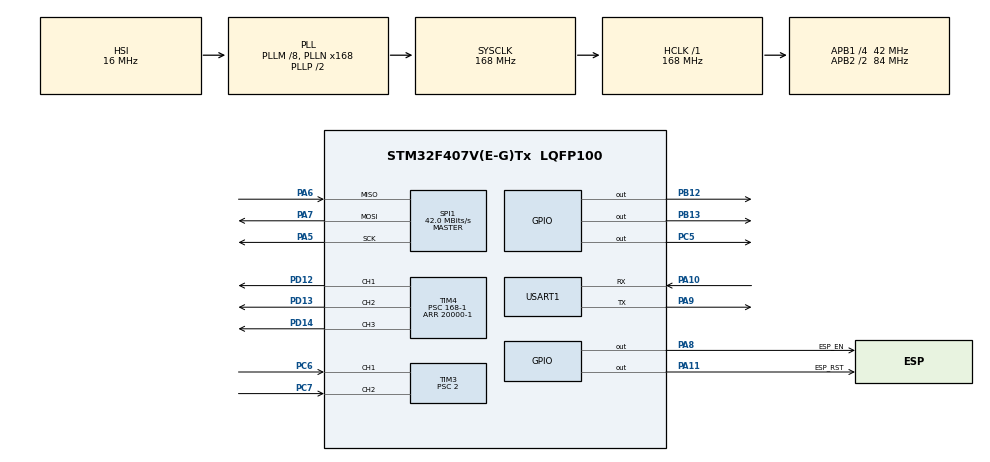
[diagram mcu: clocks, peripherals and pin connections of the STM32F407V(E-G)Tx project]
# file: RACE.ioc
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Dma.Request0=USART1_TX
Dma.Request1=USART1_RX
Dma.USART1_RX.1.Direction=DMA_PERIPH_TO_MEMORY
Dma.USART1_RX.1.FIFOMode=DMA_FIFOMODE_DISABLE
Dma.USART1_RX.1.Instance=DMA2_Stream2
Dma.USART1_RX.1.MemDataAlignment=DMA_MDATAALIGN_BYTE
Dma.USART1_RX.1.MemInc=DMA_MINC_ENABLE
Dma.USART1_RX.1.Mode=DMA_NORMAL
Dma.USART1_RX.1.PeriphDataAlignment=DMA_PDATAALIGN_BYTE
Dma.USART1_RX.1.PeriphInc=DMA_PINC_DISABLE
Dma.USART1_RX.1.Priority=DMA_PRIORITY_LOW
Dma.USART1_TX.0.Direction=DMA_MEMORY_TO_PERIPH
Dma.USART1_TX.0.FIFOMode=DMA_FIFOMODE_DISABLE
Dma.USART1_TX.0.Instance=DMA2_Stream7
Dma.USART1_TX.0.MemDataAlignment=DMA_MDATAALIGN_BYTE
Dma.USART1_TX.0.MemInc=DMA_MINC_ENABLE
Dma.USART1_TX.0.Mode=DMA_NORMAL
Dma.USART1_TX.0.PeriphDataAlignment=DMA_PDATAALIGN_BYTE
Dma.USART1_TX.0.PeriphInc=DMA_PINC_DISABLE
Dma.USART1_TX.0.Priority=DMA_PRIORITY_LOW
Mcu.Family=STM32F4
Mcu.Name=STM32F407V(E-G)Tx
Mcu.Package=LQFP100
NVIC.DMA2_Stream2_IRQn=true\:0\:0\:false\:false\:true\:false\:true\:true
NVIC.DMA2_Stream7_IRQn=true\:0\:0\:false\:false\:true\:false\:true\:true
NVIC.PriorityGroup=NVIC_PRIORITYGROUP_4
NVIC.TIM1_UP_TIM10_IRQn=true\:0\:0\:false\:false\:true\:true\:true\:true
NVIC.USART1_IRQn=true\:0\:0\:false\:false\:true\:true\:true\:true
PA10.Mode=Asynchronous
PA10.Signal=USART1_RX
PA11.GPIO_Label=ESP_RST
PA11.PinState=GPIO_PIN_SET
PA11.Signal=GPIO_Output
PA5.Mode=Full_Duplex_Master
PA5.Signal=SPI1_SCK
PA6.Mode=Full_Duplex_Master
PA6.Signal=SPI1_MISO
PA7.Mode=Full_Duplex_Master
PA7.Signal=SPI1_MOSI
PA8.GPIO_Label=ESP_EN
PA8.PinState=GPIO_PIN_RESET
PA8.Signal=GPIO_Output
PA9.Mode=Asynchronous
PA9.Signal=USART1_TX
PB12.Signal=GPIO_Output
PB13.Signal=GPIO_Output
PC5.Signal=GPIO_Output
PC6.Signal=S_TIM3_CH1
PC7.Signal=S_TIM3_CH2
PD12.Signal=S_TIM4_CH1
PD13.Signal=S_TIM4_CH2
PD14.Signal=S_TIM4_CH3
PH0-OSC_IN.Mode=HSE-External-Oscillator
PH0-OSC_IN.Signal=RCC_OSC_IN
PH1-OSC_OUT.Mode=HSE-External-Oscillator
PH1-OSC_OUT.Signal=RCC_OSC_OUT
ProjectManager.HeapSize=0x1000
ProjectManager.StackSize=0x2000
ProjectManager.TargetToolchain=MDK-ARM V5.32
RCC.48MHZClocksFreq_Value=84000000
RCC.AHBFreq_Value=168000000
RCC.APB1CLKDivider=RCC_HCLK_DIV4
RCC.APB1Freq_Value=42000000
RCC.APB1TimFreq_Value=84000000
RCC.APB2CLKDivider=RCC_HCLK_DIV2
RCC.APB2Freq_Value=84000000
RCC.APB2TimFreq_Value=168000000
RCC.CortexFreq_Value=168000000
RCC.HCLKFreq_Value=168000000
RCC.HSE_VALUE=25000000
RCC.HSI_VALUE=16000000
RCC.LSE_VALUE=32768
RCC.PLLM=8
RCC.PLLN=168
RCC.SYSCLKFreq_VALUE=168000000
RCC.SYSCLKSource=RCC_SYSCLKSOURCE_PLLCLK
RCC.VCOOutputFreq_Value=336000000
SH.S_TIM3_CH1.0=TIM3_CH1,Encoder_Interface
SH.S_TIM3_CH2.0=TIM3_CH2,Encoder_Interface
SH.S_TIM4_CH1.0=TIM4_CH1,PWM Generation1 CH1
SH.S_TIM4_CH2.0=TIM4_CH2,PWM Generation2 CH2
SH.S_TIM4_CH3.0=TIM4_CH3,PWM Generation3 CH3
SPI1.CalculateBaudRate=42.0 MBits/s
SPI1.Direction=SPI_DIRECTION_2LINES
SPI1.Mode=SPI_MODE_MASTER
SPI1.VirtualType=VM_MASTER
TIM1.Period=1000
TIM1.Prescaler=168
TIM3.Prescaler=2
TIM4.Channel-PWM\ Generation1\ CH1=TIM_CHANNEL_1
TIM4.Channel-PWM\ Generation2\ CH2=TIM_CHANNEL_2
TIM4.Channel-PWM\ Generation3\ CH3=TIM_CHANNEL_3
TIM4.Period=20000-1
TIM4.Prescaler=168-1
USART1.VirtualMode=VM_ASYNC
VP_TIM1_VS_ClockSourceINT.Mode=Internal
board=custom

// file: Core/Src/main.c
/* USER CODE BEGIN Header */
/**
  ******************************************************************************
  * @file           : main.c
  * @brief          : Main program body
  ******************************************************************************
  * @attention
  *
  * Copyright (c) 2024 STMicroelectronics.
  * All rights reserved.
  *
  * This software is licensed under terms that can be found in the LICENSE file
  * in the root directory of this software component.
  * If no LICENSE file comes with this software, it is provided AS-IS.
  *
  ******************************************************************************
  */
/* USER CODE END Header */
#include "main.h"
#include "dma.h"
#include "spi.h"
#include "tim.h"
#include "usart.h"
#include "gpio.h"

/* USER CODE BEGIN Includes */
#include "Deploy.h"
/* USER CODE END Includes */

void SystemClock_Config(void);
/* USER CODE BEGIN PFP */
void HAL_TIM_PeriodElapsedCallback(TIM_HandleTypeDef *htim){
	if(htim==&htim1)interrupt_all();
}
void HAL_UARTEx_RxEventCallback(UART_HandleTypeDef *huart, uint16_t Size){
	esp01s_callback_Rx(huart,Size);
}
void HAL_UART_TxCpltCallback(UART_HandleTypeDef *huart){
	esp01s_callback_Tx(huart);
}
/* USER CODE END PFP */

int main(void)
{

  /* MCU Configuration--------------------------------------------------------*/

  /* Reset of all peripherals, Initializes the Flash interface and the Systick. */
  HAL_Init();

  /* Configure the system clock */
  SystemClock_Config();

  /* Initialize all configured peripherals */
  MX_GPIO_Init();
  MX_DMA_Init();
  MX_TIM1_Init();
  MX_TIM4_Init();
  MX_TIM3_Init();
  MX_USART1_UART_Init();
  MX_SPI1_Init();
  /* USER CODE BEGIN 2 */
	init_all();
  /* USER CODE END 2 */

  /* Infinite loop */
  /* USER CODE BEGIN WHILE */
  while (1)
  {
		loop_all();
    /* USER CODE END WHILE */

  }
}

void SystemClock_Config(void)
{
  RCC_OscInitTypeDef RCC_OscInitStruct = {0};
  RCC_ClkInitTypeDef RCC_ClkInitStruct = {0};

  /** Configure the main internal regulator output voltage
  */
  __HAL_RCC_PWR_CLK_ENABLE();
  __HAL_PWR_VOLTAGESCALING_CONFIG(PWR_REGULATOR_VOLTAGE_SCALE1);

  /** Initializes the RCC Oscillators according to the specified parameters
  * in the RCC_OscInitTypeDef structure.
  */
  RCC_OscInitStruct.OscillatorType = RCC_OSCILLATORTYPE_HSI;
  RCC_OscInitStruct.HSIState = RCC_HSI_ON;
  RCC_OscInitStruct.HSICalibrationValue = RCC_HSICALIBRATION_DEFAULT;
  RCC_OscInitStruct.PLL.PLLState = RCC_PLL_ON;
  RCC_OscInitStruct.PLL.PLLSource = RCC_PLLSOURCE_HSI;
  RCC_OscInitStruct.PLL.PLLM = 8;
  RCC_OscInitStruct.PLL.PLLN = 168;
  RCC_OscInitStruct.PLL.PLLP = RCC_PLLP_DIV2;
  RCC_OscInitStruct.PLL.PLLQ = 4;
  if (HAL_RCC_OscConfig(&RCC_OscInitStruct) != HAL_OK)
  {
    Error_Handler();
  }

  /** Initializes the CPU, AHB and APB buses clocks
  */
  RCC_ClkInitStruct.ClockType = RCC_CLOCKTYPE_HCLK|RCC_CLOCKTYPE_SYSCLK
                              |RCC_CLOCKTYPE_PCLK1|RCC_CLOCKTYPE_PCLK2;
  RCC_ClkInitStruct.SYSCLKSource = RCC_SYSCLKSOURCE_PLLCLK;
  RCC_ClkInitStruct.AHBCLKDivider = RCC_SYSCLK_DIV1;
  RCC_ClkInitStruct.APB1CLKDivider = RCC_HCLK_DIV4;
  RCC_ClkInitStruct.APB2CLKDivider = RCC_HCLK_DIV2;

  if (HAL_RCC_ClockConfig(&RCC_ClkInitStruct, FLASH_LATENCY_5) != HAL_OK)
  {
    Error_Handler();
  }
}

void Error_Handler(void)
{
  __disable_irq();
  while (1)
  {
  }
}
